# PY32F030xx register map
Vendor: Puya; Series: PY32F0; File version: 1.0.0
CPU: CM0+ r0p1, little endian, no MPU, no FPU, 4 interrupt priority bits
Registers are 32-bit, read-write, reset 0x0 unless marked. A register's access mark holds for its fields unless they carry their own. Offsets are from the block's base; [hi:lo] are bit positions; lines under a group give offsets from that group; {n}, {i} and the like mark numbered series.

## ADC — Analog to Digital Converter
Base 0x40012400
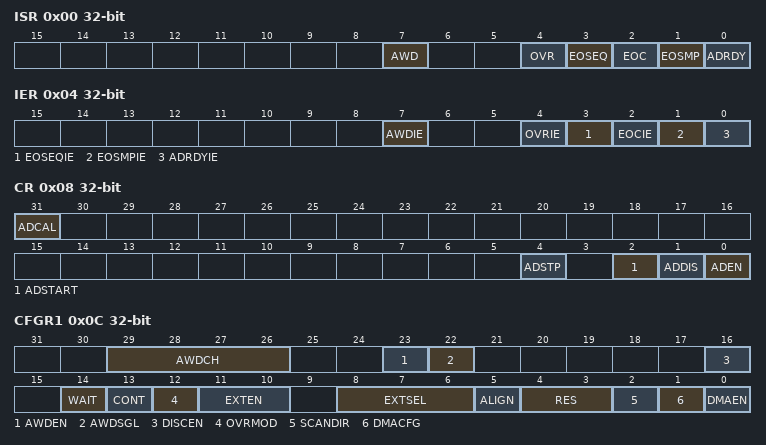
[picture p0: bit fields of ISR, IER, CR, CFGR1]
0x00 ISR — ADC interrupt and status register
  [7] AWD — ADC analog watchdog flag
    on read: 0=NoEvent (No analog watchdog event occurred); 1=Event (Analog watchdog event occurred) | on write: 1=Clear the analog watchdog event flag
  [4] OVR — ADC group regular overrun flag
    on read: 0=No overrun occurred; 1=Overrun occurred | on write: 1=Clear the overrun flag
  [3] EOSEQ — ADC group regular end of sequence conversions flag
    on read: 0=NotComplete (Conversion sequence is not complete); 1=Complete (Conversion sequence complete) | on write: 1=Clear the conversion sequence flag
  [2] EOC — ADC group regular end of unitary conversion flag
    on read: 0=NotComplete (Channel conversion is not complete); 1=Complete (Channel conversion complete) | on write: 1=Clear the channel conversion flag
  [1] EOSMP — ADC group regular end of sampling flag
    on read: 0=NotAtEnd (Not at the end of the samplings phase); 1=AtEnd (End of sampling phase reached) | on write: 1=Clear the sampling phase flag
  [0] ADRDY — ADC ready status
    on read: 0=NotReady (ADC not yet ready to start conversion); 1=Ready (ADC ready to start conversion) | on write: 1=Clear the ADC ready flag
0x04 IER — ADC interrupt enable register
  [7] AWDIE — ADC analog watchdog interrupt
    0=Disabled (Analog watchdog interrupt disabled); 1=Enabled (Analog watchdog interrupt enabled)
  [4] OVRIE — ADC group regular overrun interrupt
    0=Disabled (Overrun interrupt disabled); 1=Enabled (Overrun interrupt enabled. An interrupt is generated when the OVR bit is set.)
  [3] EOSEQIE — ADC group regular end of sequence conversions interrupt
    0=Disabled (EOSEQ interrupt disabled); 1=Enabled (EOSEQ interrupt enabled. An interrupt is generated when the EOS bit is set.)
  [2] EOCIE — ADC group regular end of unitary conversion interrupt
    0=Disabled (EOC interrupt disabled); 1=Enabled (EOC interrupt enabled. An interrupt is generated when the EOC bit is set.)
  [1] EOSMPIE — ADC group regular end of sampling interrupt
    0=Disabled (EOSMP interrupt disabled); 1=Enabled (EOSMP interrupt enabled. An interrupt is generated when the EOSMP bit is set.)
  [0] ADRDYIE — ADC ready interrupt
    0=Disabled (ADRDY interrupt disabled); 1=Enabled (ADRDY interrupt enabled. An interrupt is generated when the ADRDY bit is set.)
0x08 CR — ADC control register
  [31] ADCAL — ADC group regular conversion calibration
    on read: 0=NotCalibrating (ADC calibration either not yet performed or completed); 1=Calibrating (ADC calibration in progress) | on write: 1=StartCalibration (Start the ADC calibration sequence)
  [4] ADSTP — ADC group regular conversion stop
    on read: 0=NotStopping (No stop command active); 1=Stopping (ADC stopping conversion) | on write: 1=StopConversion (Stop the active conversion)
  [2] ADSTART — ADC group regular conversion start
    on read: 0=NotActive (No conversion ongoing); 1=Active (ADC operating and may be converting) | on write: 1=StartConversion (Start the ADC conversion (may be delayed for hardware triggers))
  [1] ADDIS — ADC disabling
    on read: 0=NotDisabling (No disable command active); 1=Disabling (ADC disabling) | on write: 1=Disable the ADC
  [0] ADEN — ADC enable
    on read: 0=Disabled (ADC disabled); 1=Enabled (ADC enabled) | on write: 1=Enabled (Enable the ADC)
0x0C CFGR1 — ADC configuration register 1
  [29:26] AWDCH range 0..13 — ADC analog watchdog monitored channel selection
  [23] AWDEN — ADC analog watchdog enable on scope ADC group regular
    0=Disabled (Analog watchdog disabled); 1=Enabled (Analog watchdog enabled)
  [22] AWDSGL — ADC analog watchdog monitoring a single channel or all channels
    0=AllChannels (Analog watchdog enabled on all channels); 1=SingleChannel (Analog watchdog enabled on a single channel)
  [16] DISCEN — ADC group regular sequencer discontinuous mode
    0=Disabled (Discontinuous mode disabled); 1=Enabled (Discontinuous mode enabled)
  [14] WAIT — Wait conversion mode
    0=Disabled (Wait conversion mode off); 1=Enabled (Wait conversion mode on)
  [13] CONT — ADC group regular continuous conversion mode
    0=Single conversion mode; 1=Continuous conversion mode
  [12] OVRMOD — ADC group regular overrun configuration
    0=Preserve (ADC_DR register is preserved with the old data when an overrun is detected); 1=Overwrite (ADC_DR register is overwritten with the last conversion result when an overrun is detected)
  [11:10] EXTEN — ADC group regular external trigger polarity
    0=Disabled (Hardware trigger detection disabled); 1=RisingEdge (Hardware trigger detection on the rising edge); 2=FallingEdge (Hardware trigger detection on the falling edge); 3=BothEdges (Hardware trigger detection on both the rising and falling edges)
  [8:6] EXTSEL — ADC group regular external trigger source
    0=TIM1_TRGO (Timer 1 TRGO event); 1=TIM1_CC4 (Timer 1 CC4 event); 2=TRG2 (Reserved); 3=TIM3_TRGP (Timer 3 TRGP event); {v}=TRG{v} (Reserved) (v=4..7)
  [5] ALIGN — ADC data alignement
    0=Right alignment; 1=Left alignment
  [4:3] RES — ADC data resolution
    0=TwelveBit (12 bits); 1=TenBit (10 bits); 2=EightBit (8 bits); 3=SixBit (6 bits)
  [2] SCANDIR — Scan sequence direction
    0=Upward scan (from CHSEL0 to CHSEL12); 1=Backward scan (from CHSEL12 to CHSEL0)
  [1] DMACFG — ADC DMA transfer configuration
    0=OneShot (DMA one shot mode selected); 1=Circular (DMA circular mode selected)
  [0] DMAEN — ADC DMA transfer enable
    0=Disabled (DMA disabled); 1=Enabled (DMA enabled)
0x10 CFGR2 — ADC configuration register 2
  [31:28] CKMODE — ADC clock mode
    0=PCLK (PCLK (Synchronous clock mode)); 1=PCLK_Div2 (PCLK/2 (Synchronous clock mode)); 2=PCLK_Div4 (PCLK/4 (Synchronous clock mode)); 3=PCLK_Div8 (PCLK/8 (Synchronous clock mode)); 4=PCLK_Div16 (PCLK/16 (Synchronous clock mode)); 5=PCLK_Div32 (PCLK/32 (Synchronous clock mode)); 6=PCLK_Div64 (PCLK/64 (Synchronous clock mode)); 8=HSI; 9=HSI_Div2 (HSI/2); 10=HSI_Div4 (HSI/4); 11=HSI_Div8 (HSI/8); 12=HSI_Div16 (HSI/16); 13=HSI_Div32 (HSI/32); 14=HSI_Div64 (HSI/64)
0x14 SMPR — ADC sampling time register
  [2:0] SMP — Sampling time selection
    0=Cycles3_5 (3.5 ADC clock cycles); 1=Cycles5_5 (5.5 ADC clock cycles); 2=Cycles7_5 (7.5 ADC clock cycles); 3=Cycles13_5 (13.5 ADC clock cycles); 4=Cycles28_5 (28.5 ADC clock cycles); 5=Cycles41_5 (41.5 ADC clock cycles); 6=Cycles71_5 (71.5 ADC clock cycles); 7=Cycles239_5 (239.5 ADC clock cycles)
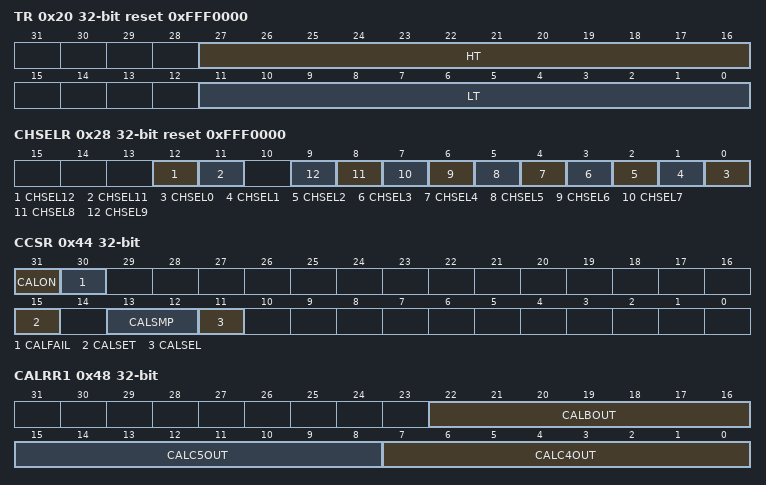
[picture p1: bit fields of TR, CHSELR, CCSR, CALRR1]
0x20 TR reset 0xFFF0000 — ADC analog watchdog 1 threshold register
  [27:16] HT range 0..2047 — ADC analog watchdog threshold high
  [11:0] LT range 0..2047 — ADC analog watchdog threshold low
0x28 CHSELR reset 0xFFF0000 — ADC group regular sequencer register
  [all] fields
    0=NotSelected (Input Channel is not selected for conversion); 1=Selected (Input Channel is selected for conversion)
  [12] CHSEL12 — Channel-12 selection
  [11] CHSEL11 — Channel-11 selection
  [n] CHSEL{n} (n=0..9) — Channel-{n} selection
0x40 DR ro — ADC group regular data register
  [15:0] DATA — ADC group regular conversion data
0x44 CCSR — ADC calibration configuration and status register
  [31] CALON ro — Calibration flag
    0=Off (Calibration off); 1=On (Calibration on)
  [30] CALFAIL — Calibration fail flag
    on read: 0=Succeed (Calibration succeed); 1=Failed (Calibration failed) | on write: 1=Clear the calibration fail flag
  [15] CALSET — Calibration factor selection
  [13:12] CALSMP — Calibration sample time selection
    0=TowCycles (Calibration sample time is 2 cycles); 1=FourCycles (Calibration sample time is 4 cycles); 2=EightCycles (Calibration sample time is 8 cycles); 3=OneCycles (Calibration sample time is 1 cycles)
  [11] CALSEL — Calibration contents selection
    0=OffsetAndLinearity (Calibrate offset and linearity); 1=OffsetOnly (Calibrate offset only)
0x48 CALRR1 ro — ADC calibration result register 1
  [22:16] CALBOUT — offset result
  [15:8] CALC5OUT — C5 result
  [7:0] CALC4OUT — C4 result
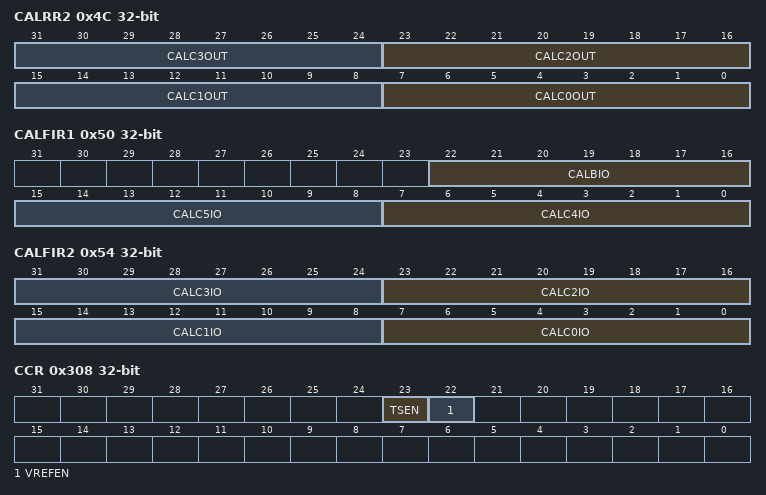
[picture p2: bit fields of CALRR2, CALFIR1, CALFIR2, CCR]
0x4C CALRR2 ro — ADC calibration result register 2
  [8n+7:8n] CALC{n}OUT (n=0..3) — C{n} result
0x50 CALFIR1 — ADC calibration factor input register 1
  [22:16] CALBIO — Calibration offset factor input
  [15:8] CALC5IO — Calibration C5 factor input
  [7:0] CALC4IO — Calibration C4 factor input
0x54 CALFIR2 — ADC calibration factor input register 2
  [8n+7:8n] CALC{n}IO (n=0..3) — Calibration C{n} factor input
0x308 CCR — ADC common configuration register
  [23] TSEN — Temperature sensor enable
    0=Disabled (Temperature sensor disabled); 1=Enabled (Temperature sensor enabled)
  [22] VREFEN — VREFINT enable
    0=Disabled (VREFINT disabled); 1=Enabled (VREFINT enabled)
